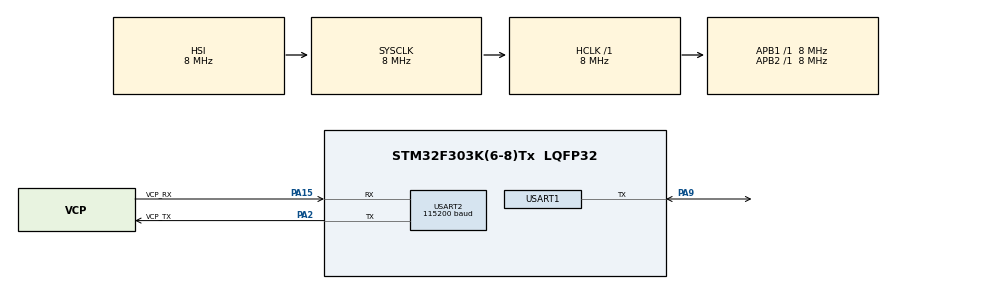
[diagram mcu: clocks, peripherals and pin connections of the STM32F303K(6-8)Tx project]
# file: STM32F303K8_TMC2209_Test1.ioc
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Mcu.Family=STM32F3
Mcu.Name=STM32F303K(6-8)Tx
Mcu.Package=LQFP32
NVIC.PriorityGroup=NVIC_PRIORITYGROUP_4
PA13.GPIO_Label=SWDIO
PA13.Mode=Serial_Wire
PA13.Signal=SYS_JTMS-SWDIO
PA14.GPIO_Label=SWCLK
PA14.Mode=Serial_Wire
PA14.Signal=SYS_JTCK-SWCLK
PA15.GPIO_Label=VCP_RX
PA15.Mode=Asynchronous
PA15.Signal=USART2_RX
PA2.GPIO_Label=VCP_TX
PA2.Mode=Asynchronous
PA2.Signal=USART2_TX
PA9.Mode=Half_duplex(single_wire_mode)
PA9.Signal=USART1_TX
PF0\ /\ OSC_IN.GPIO_Label=MCO
PF0\ /\ OSC_IN.Mode=HSE-External-Clock-Source
PF0\ /\ OSC_IN.Signal=RCC_OSC_IN
ProjectManager.HeapSize=0x200
ProjectManager.StackSize=0x400
ProjectManager.TargetToolchain=STM32CubeIDE
RCC.AHBFreq_Value=8000000
RCC.APB1Freq_Value=8000000
RCC.APB2Freq_Value=8000000
RCC.CortexFreq_Value=8000000
RCC.HSE_VALUE=8000000
RCC.HSI_VALUE=8000000
RCC.SYSCLKFreq_VALUE=8000000
USART1.VirtualMode-Half_duplex(single_wire_mode)=VM_ASYNC
USART2.BaudRate=115200
USART2.VirtualMode-Asynchronous=VM_ASYNC
board=NUCLEO-F303K8

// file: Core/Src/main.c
/* USER CODE BEGIN Header */
/**
  ******************************************************************************
  * @file           : main.c
  * @brief          : Main program body
  ******************************************************************************
  * @attention
  *
  * Copyright (c) 2022 STMicroelectronics.
  * All rights reserved.
  *
  * This software is licensed under terms that can be found in the LICENSE file
  * in the root directory of this software component.
  * If no LICENSE file comes with this software, it is provided AS-IS.
  *
  ******************************************************************************
  */
/* USER CODE END Header */
#include "main.h"

/* USER CODE BEGIN Includes */
#include <stdio.h>
#include "TMC2209.h"
/* USER CODE END Includes */

/* USER CODE BEGIN PD */
#define TMC2209_CRC(data, length) tmc_CRC8(data, length, 1)
/* USER CODE END PD */

 UART_HandleTypeDef huart1;
UART_HandleTypeDef huart2;

/* USER CODE BEGIN PV */
static TMC2209TypeDef TMC2209; //TMC2209の設定などの定義
static ConfigurationTypeDef TMC2209_config; //TMC2209の設定
/* USER CODE END PV */

void SystemClock_Config(void);
static void MX_GPIO_Init(void);
static void MX_USART2_UART_Init(void);
static void MX_USART1_UART_Init(void);
/* USER CODE BEGIN PFP */
static void periodicJob(uint32_t tick);
static uint8_t reset(void);
static uint8_t restore(void);
void TMC2209_INIT(void);
/* USER CODE END PFP */

/* USER CODE BEGIN 0 */
void tmc2209_readWriteArray(uint8_t channel, uint8_t *data, size_t writeLength, size_t readLength)
{
	//set your uart read write
	//UART_readWrite(channelToUART(channel), data, writeLength, readLength);
	HAL_HalfDuplex_EnableTransmitter(&huart1);
	HAL_UART_Transmit(&huart1, data, writeLength,3000);

	if(readLength > 0){
		HAL_HalfDuplex_EnableReceiver(&huart1);
		HAL_UART_Receive(&huart1, data, readLength, 3000);
	}
}

uint8_t tmc2209_CRC8(uint8_t *data, size_t length)
{
	return TMC2209_CRC(data, length);
}

static void periodicJob(uint32_t tick)
{

	tmc2209_periodicJob(&TMC2209, tick);

	//StepDir_periodicJob(0);
}

static uint8_t reset()
{
	//StepDir_init(STEPDIR_PRECISION);
	//StepDir_setPins(0, Pins.STEP, Pins.DIR, Pins.DIAG);

	return tmc2209_reset(&TMC2209);
}

static uint8_t restore()
{
	return tmc2209_restore(&TMC2209);
}

void TMC2209_INIT()
{
	tmc_fillCRC8Table(0x07, true, 1);

	TMC2209_config.reset = reset;
	TMC2209_config.restore = restore;

	tmc2209_init(&TMC2209, 0, 0, &TMC2209_config, &tmc2209_defaultRegisterResetState[0]);

	//restore();
}

/* USER CODE END 0 */

int main(void)
{
  /* USER CODE BEGIN 1 */
   setbuf(stdout, NULL);
  /* USER CODE END 1 */

  /* MCU Configuration--------------------------------------------------------*/

  /* Reset of all peripherals, Initializes the Flash interface and the Systick. */
  HAL_Init();

  /* Configure the system clock */
  SystemClock_Config();

  /* Initialize all configured peripherals */
  MX_GPIO_Init();
  MX_USART2_UART_Init();
  MX_USART1_UART_Init();
  /* USER CODE BEGIN 2 */
  TMC2209_INIT();
  /* USER CODE END 2 */

  /* Infinite loop */
  while (1)
  {

    /* USER CODE BEGIN 3 */
	  printf("Hello\r\n");
	  HAL_Delay(1000);
  }
  /* USER CODE END 3 */
}

void SystemClock_Config(void)
{
  RCC_OscInitTypeDef RCC_OscInitStruct = {0};
  RCC_ClkInitTypeDef RCC_ClkInitStruct = {0};
  RCC_PeriphCLKInitTypeDef PeriphClkInit = {0};

  /** Initializes the RCC Oscillators according to the specified parameters
  * in the RCC_OscInitTypeDef structure.
  */
  RCC_OscInitStruct.OscillatorType = RCC_OSCILLATORTYPE_HSI;
  RCC_OscInitStruct.HSIState = RCC_HSI_ON;
  RCC_OscInitStruct.HSICalibrationValue = RCC_HSICALIBRATION_DEFAULT;
  RCC_OscInitStruct.PLL.PLLState = RCC_PLL_NONE;
  if (HAL_RCC_OscConfig(&RCC_OscInitStruct) != HAL_OK)
  {
    Error_Handler();
  }

  /** Initializes the CPU, AHB and APB buses clocks
  */
  RCC_ClkInitStruct.ClockType = RCC_CLOCKTYPE_HCLK|RCC_CLOCKTYPE_SYSCLK
                              |RCC_CLOCKTYPE_PCLK1|RCC_CLOCKTYPE_PCLK2;
  RCC_ClkInitStruct.SYSCLKSource = RCC_SYSCLKSOURCE_HSI;
  RCC_ClkInitStruct.AHBCLKDivider = RCC_SYSCLK_DIV1;
  RCC_ClkInitStruct.APB1CLKDivider = RCC_HCLK_DIV1;
  RCC_ClkInitStruct.APB2CLKDivider = RCC_HCLK_DIV1;

  if (HAL_RCC_ClockConfig(&RCC_ClkInitStruct, FLASH_LATENCY_0) != HAL_OK)
  {
    Error_Handler();
  }
  PeriphClkInit.PeriphClockSelection = RCC_PERIPHCLK_USART1;
  PeriphClkInit.Usart1ClockSelection = RCC_USART1CLKSOURCE_PCLK1;
  if (HAL_RCCEx_PeriphCLKConfig(&PeriphClkInit) != HAL_OK)
  {
    Error_Handler();
  }
}

static void MX_USART1_UART_Init(void)
{

  huart1.Instance = USART1;
  huart1.Init.BaudRate = 38400;
  huart1.Init.WordLength = UART_WORDLENGTH_8B;
  huart1.Init.StopBits = UART_STOPBITS_1;
  huart1.Init.Parity = UART_PARITY_NONE;
  huart1.Init.Mode = UART_MODE_TX_RX;
  huart1.Init.HwFlowCtl = UART_HWCONTROL_NONE;
  huart1.Init.OverSampling = UART_OVERSAMPLING_16;
  huart1.Init.OneBitSampling = UART_ONE_BIT_SAMPLE_DISABLE;
  huart1.AdvancedInit.AdvFeatureInit = UART_ADVFEATURE_NO_INIT;
  if (HAL_HalfDuplex_Init(&huart1) != HAL_OK)
  {
    Error_Handler();
  }

}

static void MX_USART2_UART_Init(void)
{

  huart2.Instance = USART2;
  huart2.Init.BaudRate = 115200;
  huart2.Init.WordLength = UART_WORDLENGTH_8B;
  huart2.Init.StopBits = UART_STOPBITS_1;
  huart2.Init.Parity = UART_PARITY_NONE;
  huart2.Init.Mode = UART_MODE_TX_RX;
  huart2.Init.HwFlowCtl = UART_HWCONTROL_NONE;
  huart2.Init.OverSampling = UART_OVERSAMPLING_16;
  huart2.Init.OneBitSampling = UART_ONE_BIT_SAMPLE_DISABLE;
  huart2.AdvancedInit.AdvFeatureInit = UART_ADVFEATURE_NO_INIT;
  if (HAL_UART_Init(&huart2) != HAL_OK)
  {
    Error_Handler();
  }

}

static void MX_GPIO_Init(void)
{

  /* GPIO Ports Clock Enable */
  __HAL_RCC_GPIOF_CLK_ENABLE();
  __HAL_RCC_GPIOA_CLK_ENABLE();

}

/* USER CODE BEGIN 4 */
int _write(int file, char *ptr, int len)
{
  HAL_UART_Transmit(&huart2,(uint8_t *)ptr,len,10);
  return len;
}

/* USER CODE END 4 */

void Error_Handler(void)
{
  __disable_irq();
  while (1)
  {
  }
}
